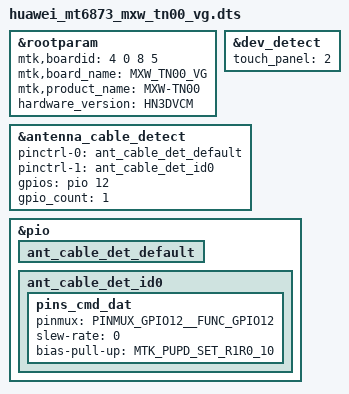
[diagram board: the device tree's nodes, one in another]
#include <dt-bindings/interrupt-controller/arm-gic.h>
#include <dt-bindings/interrupt-controller/irq.h>
#include <dt-bindings/pinctrl/mt6873-pinfunc.h>
#include <dt-bindings/clock/mt6873-clk.h>
/dts-v1/;
/plugin/;

#include "huawei_common/huawei_common.dtsi"
#include "huawei_mt6873_mxw_tn00_vg/huawei.dtsi"

&rootparam {
    mtk,boardid = <4 0 8 5>;
    mtk,board_name = "MXW_TN00_VG";
    mtk,product_name = "MXW-TN00";
    hardware_version = "HN3DVCM";
};

&dev_detect{
    touch_panel = <2>;
    status = "ok";
};

&antenna_cable_detect {
	pinctrl-names = "default", "id0";
	pinctrl-0 = <&ant_cable_det_default>;
	pinctrl-1 = <&ant_cable_det_id0>;
	gpios = <&pio 12 0 >;
	gpio_count = <1>;
};

&pio {
	ant_cable_det_default: ant_cable_det_default {
	};

	ant_cable_det_id0: ant_cable_det_id0 {
		pins_cmd_dat {
			pinmux = <PINMUX_GPIO12__FUNC_GPIO12>;
			slew-rate = <0>;
			bias-pull-up = <MTK_PUPD_SET_R1R0_10>;
		};
	};
};

#include <k6873v1_64/cust.dtsi>

/*End of this file, DO NOT ADD ANYTHING HERE*/

